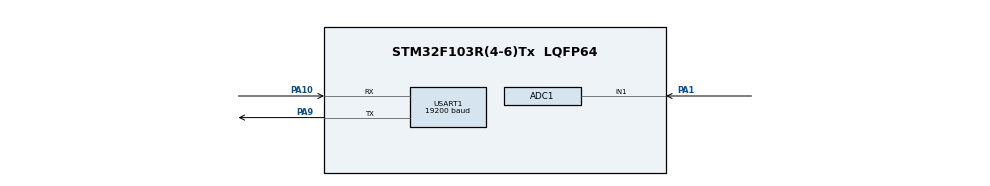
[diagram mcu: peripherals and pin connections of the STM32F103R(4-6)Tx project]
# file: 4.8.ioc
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ADC1.Channel-0\#ChannelRegularConversion=ADC_CHANNEL_1
ADC1.DataAlign=ADC_DATAALIGN_RIGHT
ADC1.NbrOfConversionFlag=1
ADC1.Rank-0\#ChannelRegularConversion=1
ADC1.SamplingTime-0\#ChannelRegularConversion=ADC_SAMPLETIME_1CYCLE_5
ADC1.master=1
Mcu.Family=STM32F1
Mcu.Name=STM32F103R(4-6)Tx
Mcu.Package=LQFP64
NVIC.PriorityGroup=NVIC_PRIORITYGROUP_4
NVIC.USART1_IRQn=true\:0\:0\:false\:false\:true\:true\:true
PA1.Signal=ADCx_IN1
PA10.Mode=Asynchronous
PA10.Signal=USART1_RX
PA9.Mode=Asynchronous
PA9.Signal=USART1_TX
ProjectManager.HeapSize=0x200
ProjectManager.StackSize=0x400
ProjectManager.TargetToolchain=STM32CubeIDE
RCC.APB1Freq_Value=8000000
RCC.APB2Freq_Value=8000000
SH.ADCx_IN1.0=ADC1_IN1,IN1
USART1.BaudRate=19200
USART1.VirtualMode=VM_ASYNC
VP_SYS_VS_ND.Mode=No_Debug
board=custom

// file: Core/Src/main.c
/* USER CODE BEGIN Header */
/**
  ******************************************************************************
  * @file           : main.c
  * @brief          : Main program body
  ******************************************************************************
  * @attention
  *
  * <h2><center>&copy; Copyright (c) 2020 STMicroelectronics.
  * All rights reserved.</center></h2>
  *
  * This software component is licensed by ST under BSD 3-Clause license,
  * the "License"; You may not use this file except in compliance with the
  * License. You may obtain a copy of the License at:
  *                        opensource.org/licenses/BSD-3-Clause
  *
  ******************************************************************************
  */
/* USER CODE END Header */

#include "main.h"

/* USER CODE BEGIN Includes */
#include "stdio.h"

/* USER CODE END Includes */

ADC_HandleTypeDef hadc1;
UART_HandleTypeDef huart1;

/* USER CODE BEGIN PV */
//温度t-数字量D 关系数组
const uint32_t tD[]=
{
	3178,  //t=0
	3139,3099,3059,3017,2975,2932,2888,2844,2799,2754,  //t=1~10
	2708,2662,2615,2569,2521,2474,2427,2379,2331,2284,  //t=11~20
	2236,2189,2141,2094,2048,2001,1955,1909,1864,1819,  //t=21~30
	1775,1731,1688,1645,1603,1562,1522,1482,1442,1404   //t=31~40
};

/* USER CODE END PV */

void SystemClock_Config(void);
static void MX_GPIO_Init(void);
static void MX_ADC1_Init(void);
static void MX_USART1_UART_Init(void);
/* USER CODE BEGIN PFP */
float D2t(uint32_t D);
/* USER CODE END PFP */

int main(void)
{
  /* USER CODE BEGIN 1 */
	ADC_ChannelConfTypeDef sConfig = {0};  //建立sConfig结构体
	char str[20];
	float t;
	uint32_t adcv;
  /* USER CODE END 1 */

  /* MCU Configuration--------------------------------------------------------*/

  /* Reset of all peripherals, Initializes the Flash interface and the Systick. */
  HAL_Init();

  /* USER CODE BEGIN Init */
	sConfig.Rank = ADC_REGULAR_RANK_1;
	sConfig.SamplingTime = ADC_SAMPLETIME_1CYCLE_5;
  /* USER CODE END Init */

  /* Configure the system clock */
  SystemClock_Config();

  /* Initialize all configured peripherals */
  MX_GPIO_Init();
  MX_ADC1_Init();
  MX_USART1_UART_Init();

  /* Infinite loop */
  /* USER CODE BEGIN WHILE */
  while (1)
  {
	  sConfig.Channel = ADC_CHANNEL_1;  //选择通道1
	  HAL_ADC_ConfigChannel(&hadc1, &sConfig);
	  HAL_ADC_Start(&hadc1);
	  HAL_ADC_PollForConversion(&hadc1,10);
	  adcv=HAL_ADC_GetValue(&hadc1);
	  HAL_ADC_Stop(&hadc1);
	  t=D2t(adcv);
	  sprintf(str,"%f",t);
	  HAL_UART_Transmit(&huart1,&"temperature:",12,10);
	  HAL_UART_Transmit(&huart1,str,5,10);
	  HAL_UART_Transmit(&huart1,&"\n\r",2,10);
	  HAL_Delay(1000);
    /* USER CODE END WHILE */

  }
}

void SystemClock_Config(void)
{
  RCC_OscInitTypeDef RCC_OscInitStruct = {0};
  RCC_ClkInitTypeDef RCC_ClkInitStruct = {0};
  RCC_PeriphCLKInitTypeDef PeriphClkInit = {0};

  /** Initializes the CPU, AHB and APB busses clocks
  */
  RCC_OscInitStruct.OscillatorType = RCC_OSCILLATORTYPE_HSI;
  RCC_OscInitStruct.HSIState = RCC_HSI_ON;
  RCC_OscInitStruct.HSICalibrationValue = RCC_HSICALIBRATION_DEFAULT;
  RCC_OscInitStruct.PLL.PLLState = RCC_PLL_NONE;
  if (HAL_RCC_OscConfig(&RCC_OscInitStruct) != HAL_OK)
  {
    Error_Handler();
  }
  /** Initializes the CPU, AHB and APB busses clocks
  */
  RCC_ClkInitStruct.ClockType = RCC_CLOCKTYPE_HCLK|RCC_CLOCKTYPE_SYSCLK
                              |RCC_CLOCKTYPE_PCLK1|RCC_CLOCKTYPE_PCLK2;
  RCC_ClkInitStruct.SYSCLKSource = RCC_SYSCLKSOURCE_HSI;
  RCC_ClkInitStruct.AHBCLKDivider = RCC_SYSCLK_DIV1;
  RCC_ClkInitStruct.APB1CLKDivider = RCC_HCLK_DIV1;
  RCC_ClkInitStruct.APB2CLKDivider = RCC_HCLK_DIV1;

  if (HAL_RCC_ClockConfig(&RCC_ClkInitStruct, FLASH_LATENCY_0) != HAL_OK)
  {
    Error_Handler();
  }
  PeriphClkInit.PeriphClockSelection = RCC_PERIPHCLK_ADC;
  PeriphClkInit.AdcClockSelection = RCC_ADCPCLK2_DIV2;
  if (HAL_RCCEx_PeriphCLKConfig(&PeriphClkInit) != HAL_OK)
  {
    Error_Handler();
  }
}

static void MX_ADC1_Init(void)
{

  ADC_ChannelConfTypeDef sConfig = {0};

  /** Common config
  */
  hadc1.Instance = ADC1;
  hadc1.Init.ScanConvMode = ADC_SCAN_DISABLE;
  hadc1.Init.ContinuousConvMode = DISABLE;
  hadc1.Init.DiscontinuousConvMode = DISABLE;
  hadc1.Init.ExternalTrigConv = ADC_SOFTWARE_START;
  hadc1.Init.DataAlign = ADC_DATAALIGN_RIGHT;
  hadc1.Init.NbrOfConversion = 1;
  if (HAL_ADC_Init(&hadc1) != HAL_OK)
  {
    Error_Handler();
  }
  /** Configure Regular Channel
  */
  sConfig.Channel = ADC_CHANNEL_1;
  sConfig.Rank = ADC_REGULAR_RANK_1;
  sConfig.SamplingTime = ADC_SAMPLETIME_1CYCLE_5;
  if (HAL_ADC_ConfigChannel(&hadc1, &sConfig) != HAL_OK)
  {
    Error_Handler();
  }

}

static void MX_USART1_UART_Init(void)
{

  huart1.Instance = USART1;
  huart1.Init.BaudRate = 19200;
  huart1.Init.WordLength = UART_WORDLENGTH_8B;
  huart1.Init.StopBits = UART_STOPBITS_1;
  huart1.Init.Parity = UART_PARITY_NONE;
  huart1.Init.Mode = UART_MODE_TX_RX;
  huart1.Init.HwFlowCtl = UART_HWCONTROL_NONE;
  huart1.Init.OverSampling = UART_OVERSAMPLING_16;
  if (HAL_UART_Init(&huart1) != HAL_OK)
  {
    Error_Handler();
  }

}

static void MX_GPIO_Init(void)
{

  /* GPIO Ports Clock Enable */
  __HAL_RCC_GPIOA_CLK_ENABLE();

}

/* USER CODE BEGIN 4 */
//根据ADC转换结果计算温度值
float D2t(uint32_t D)
{
	uint32_t D1,D2,i;
	float t=0,t1;
	for(i=0;i<=39;i++)
	{
		if(D>=tD[i+1] && D<=tD[i])
		{
			D1=tD[i];
			D2=tD[i+1];
			t1=(float)i;
			t=(float)(D1-D)/(float)(D1-D2)+t1;
			break;
		}
	}
	return t;
}
/* USER CODE END 4 */

void Error_Handler(void)
{
}

/************************ (C) COPYRIGHT STMicroelectronics *****END OF FILE****/
